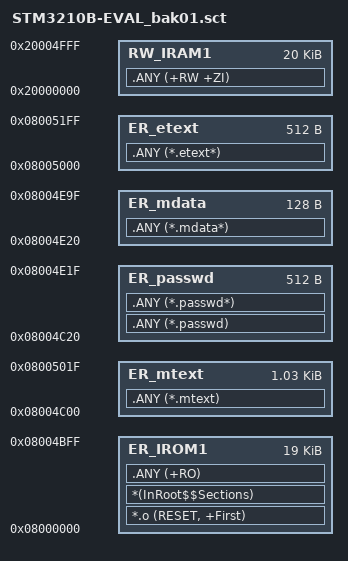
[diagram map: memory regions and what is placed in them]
; *************************************************************
; *** Scatter-Loading Description File generated by uVision ***
; *************************************************************

;// 19K 0x4C00
#define  mtext_start               0x08004C00	/* Passwd */
#define  mtext_size                0x0020   /* 32B */
#define  etext_start               0x08004C20	/* erase Code */
#define  etext_size                0x0200   /* 512B */
#define  mdata_start               0x08004E20	/* Data */
#define  mdata_size                0x0080   /* 128B */

LR_IROM1 0x08000000 0x00020000  {    ; load region size_region
  ER_IROM1 0x08000000 0x00004C00  {  ; load address = execution address
   *.o (RESET, +First)
   *(InRoot$$Sections)
   .ANY (+RO)
  }
  RW_IRAM1 0x20000000 0x00005000  {  ; RW data
   .ANY (+RW +ZI)
  }
;  ER_mtext mtext_start mtext_size  { ; load address = execution address
;   .ANY (.mtext)
;  }
;  ER_etext etext_start etext_size  { ; load address = execution address
;   .ANY (.etext)
;  }
;  ER_rtext rtext_start rtext_size  { ; load address = execution address
;   .ANY (.rtext)
;  }
  ER_mtext 0x08004C00 0x0420  { ; /* Passwd 32B */
   ;.ANY (*.passwd*)
   .ANY (*.mtext)
   ;.mtext_start_ = .
   ;.ANY (*.rtext*)
   ;.ANY (*.etext*)
   ;.ANY (*.mtextp)
  }
  ER_passwd 0x08004C20 0x0200  { ; /* Passwd 512K */
   .ANY (*.passwd)
   .ANY (*.passwd*)
   ;.ANY (*.mtext1*)
  }
  ;ER_etext 0x08004C20 0x0200  { ; /* erase Code 512B*/
  ER_etext 0x08005000 0x0200  { ; /* erase Code 512B*/
   .ANY (*.etext*)
   ;*.o (.etext)
   ;erasecode.o (.etext)
  }
  ER_mdata 0x08004E20 0x0080  { ; /* Data 128B*/
   .ANY (*.mdata*)
   ;*.o (.rtext)
   ;*(.rtext)
  }

}
;LR_etext 0x08004C20 0x4200  {
;}

